# C64 register map
Vendor: Commodore Business Machines; Series: Commodore 64; File version: 0.1.0
CPU: other r0p0, little endian, no MPU, no FPU, 2 interrupt priority bits
Registers are 8-bit, read-write, no defined reset value unless marked. A register's access mark holds for its fields unless they carry their own. Offsets are from the block's base; [hi:lo] are bit positions; {n}, {i} and the like mark numbered series; 'fields as' and 'values as' point back to an identical list.

## CIA1 — MOS 6526 CIA 1 at 0xDC00 (image repeats every 0x10 bytes through 0xDCFF): keyboard matrix, joysticks, paddle select, Datassette read (FLAG1), timers. IRQ output drives the 6510 IRQ line. TOD pin receives mains-derived 50/60 Hz. SP1/CNT1 are available on the user port.
Base 0x0000DC00
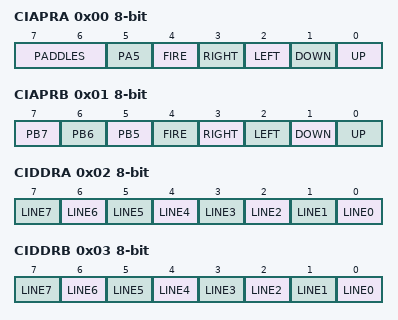
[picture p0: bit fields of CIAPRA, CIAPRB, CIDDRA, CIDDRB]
0x00 CIAPRA — Port A. Doubles as keyboard-matrix column drive (outputs, active low) and joystick port 2 (bits 0-4, active low). Bits 6-7 select which control port's paddles reach SID POTX/POTY.
  [7:6] PADDLES — Selects which control port's paddles are digitized by SID POTX/POTY: 1 = port 1, 2 = port 2
    1=Port1; 2=Port2
  [5] PA5 — Keyboard column 5
  [4] FIRE — Joystick 2 fire (also keyboard column 4). Active low.
    0=Pressed; 1=Released
  [3] RIGHT — Joystick 2 right (also keyboard column 3). Active low.
    0=Pushed; 1=Released
  [2] LEFT — Joystick 2 left (also keyboard column 2). Active low.
    0=Pushed; 1=Released
  [1] DOWN — Joystick 2 down (also keyboard column 1). Active low.
    0=Pushed; 1=Released
  [0] UP — Joystick 2 up (also keyboard column 0). Active low.
    0=Pushed; 1=Released
0x01 CIAPRB — Port B. Doubles as keyboard-matrix row sense (inputs, active low) and joystick port 1 (bits 0-4, active low; the fire line also triggers the light pen). PB6/PB7 can output timer A/B underflow.
  [7] PB7 — Timer B underflow output when CIACRB.SELECT_TIMER_OUTPUT is set; otherwise general I/O
  [6] PB6 — Timer A underflow output when CIACRA.SELECT_TIMER_OUTPUT is set; otherwise general I/O
  [5] PB5 — Keyboard row 5
  [4] FIRE — Joystick 1 fire, also the light pen trigger (also keyboard row 4). Active low.
    0=Pressed; 1=Released
  [3] RIGHT — Joystick 1 right (also keyboard row 3). Active low.
    0=Pushed; 1=Released
  [2] LEFT — Joystick 1 left (also keyboard row 2). Active low.
    0=Pushed; 1=Released
  [1] DOWN — Joystick 1 down (also keyboard row 1). Active low.
    0=Pushed; 1=Released
  [0] UP — Joystick 1 up (also keyboard row 0). Active low.
    0=Pushed; 1=Released
0x02 CIDDRA — Port A data direction (1 = output)
  [all] fields
    0=Input; 1=Output
  [n] LINE{n} (n=0..7) — Direction of Data Port A bit {n}
0x03 CIDDRB — Port B data direction (1 = output)
  [all] fields
    0=Input; 1=Output
  [n] LINE{n} (n=0..7) — Direction of Data Port B bit {n}
0x04 TIMALO — Timer A bits 7:0. Read: current count. Write: latch (reload value). HI/LO reads are not latched together, so a 16-bit read can tear across a decrement: read HI, LO, re-read HI and retry on change, or stop the timer.
  [7:0] TIMER — Timer A, low 8 bits (read: counter; write: latch)
0x05 TIMAHI — Timer A bits 15:8. Read: current count. Write: latch; if the timer is stopped, writing also loads the counter.
  [7:0] TIMER — Timer A, high 8 bits (read: counter; write: latch)
0x06 TIMBLO — Timer B bits 7:0 (as TALO)
  [7:0] TIMER — Timer B, low 8 bits (read: counter; write: latch)
0x07 TIMBHI — Timer B bits 15:8 (as TAHI)
  [7:0] TIMER — Timer B, high 8 bits (read: counter; write: latch)
0x08 TODTEN — TOD tenths of seconds, BCD. SIDE-EFFECT: reading releases the latch set by reading TODHRS; writing (in clock mode) restarts the clock; CIACRB.TOD_WRITE_MODE selects whether writes set the clock or the alarm.
  [3:0] TENTHS — Tenths, BCD
0x09 TODSEC — TOD seconds, BCD. SIDE-EFFECT: writes set the clock or the alarm per CIACRB.TOD_WRITE_MODE; the read value is frozen while the TODHRS/TODTEN latch is held.
  [6:0] SECONDS — Seconds 00-59, BCD
0x0A TODMIN — TOD minutes, BCD. SIDE-EFFECT: writes set the clock or the alarm per CIACRB.TOD_WRITE_MODE; the read value is frozen while the TODHRS/TODTEN latch is held.
  [6:0] MINUTES — Minutes 00-59, BCD
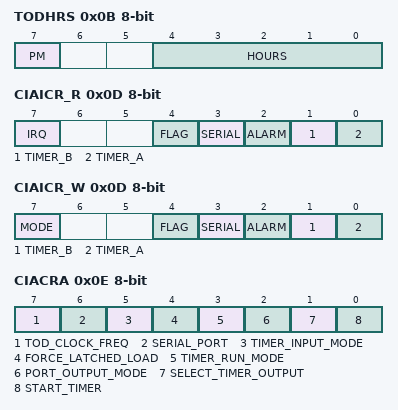
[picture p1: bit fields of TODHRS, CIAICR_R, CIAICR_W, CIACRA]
0x0B TODHRS — TOD hours, BCD, 12-hour with PM flag. SIDE-EFFECT: reading latches all four TOD registers until TODTEN is read; writing (in clock mode) stops the clock until TODTEN is written; CIACRB.TOD_WRITE_MODE selects whether writes set the clock or the alarm.
  [7] PM — 1 = PM
    0=Am; 1=Pm
  [4:0] HOURS — Hours 01-12, BCD
0x0C CIASDR — Serial shift register on SP pin, clocked by CNT; direction set by CRA.SPMODE. Output rate is timer A underflow / 2.
  [7:0] DATA — Serial shift-register byte
0x0D CIAICR_R ro read-clears — Interrupt data (read-only view of 0xDC0D, asserts IRQ): which sources have fired. Bit 7 (IR) reads Latched if any enabled source is pending. SIDE-EFFECT: reading clears all flags and releases the line, so capture everything from one read. Set the mask via CIAICR_W.
  [all] fields
    0=Inactive; 1=Latched
  [7] IRQ — Any enabled source latched (this read also clears all flags)
  [4] FLAG — FLAG pin negative edge (CIA1: Datassette read)
  [3] SERIAL — Serial register full/empty
  [2] ALARM — TOD alarm match
  [1] TIMER_B — Timer B underflow
  [0] TIMER_A — Timer A underflow
0x0D CIAICR_W wo (alternate view of CIAICR_R) — Interrupt mask (write-only alternate view of 0xDC0D). Enable or disable individual interrupt sources without disturbing the others: `set()` the sources you want to change, then let `mode()` pick the direction — `mode().enabled()` enables every source you `set()`, `mode().disabled()` disables them. Sources left `clear()` (the default) are untouched either way. Read status via CIAICR_R. SIDE-EFFECT: this write changes which interrupts are enabled.
  [7] MODE — Direction for this write: `enabled()` enables every source bit you `set()`; `disabled()` disables them. Sources left `clear()` are untouched either way. SIDE-EFFECT: the (un)mask takes effect immediately.
    0=Disabled; 1=Enabled
  [4] FLAG — FLAG interrupt mask select. `set()` marks the FLAG source for change; the direction (enable vs disable) comes from `mode()`. `clear()` (default) leaves it untouched. Setting this alone does nothing without `mode()`.
    0=Clear (Leave this source's mask unchanged); 1=Set (Select this source for the update chosen by MODE)
  [3] SERIAL — Serial interrupt mask select. `set()` marks the serial source for change; the direction (enable vs disable) comes from `mode()`. `clear()` (default) leaves it untouched. Setting this alone does nothing without `mode()`.
    values as FLAG
  [2] ALARM — TOD alarm interrupt mask select. `set()` marks the alarm for change; the direction (enable vs disable) comes from `mode()`. `clear()` (default) leaves it untouched. Setting this alone does nothing without `mode()`.
    values as FLAG
  [1] TIMER_B — Timer B interrupt mask select. `set()` marks Timer B for change; the direction (enable vs disable) comes from `mode()`. `clear()` (default) leaves Timer B untouched. Setting this alone does nothing without `mode()`.
    values as FLAG
  [0] TIMER_A — Timer A interrupt mask select. `set()` marks Timer A for change; the direction (enable vs disable) comes from `mode()`. `clear()` (default) leaves Timer A untouched. Setting this alone does nothing without `mode()`.
    values as FLAG
0x0E CIACRA — Control register A. Bit 4 (FORCE_LATCHED_LOAD) is a write-only strobe that always reads back 0, so it appears on the writer only
  [7] TOD_CLOCK_FREQ — TOD clock input frequency
    0=Hz60; 1=Hz50
  [6] SERIAL_PORT — Serial-port shift-register direction
    0=Input; 1=Output
  [5] TIMER_INPUT_MODE — What timer A counts
    0=CpuCycles; 1=UserPortCnt
  [4] FORCE_LATCHED_LOAD wo — Force-load timer A from its latch. A strobe: writing Execute performs the load, writing Idle does nothing. Write-only, hence no reader: the bit always reads back Idle no matter what was last written, so a read carries no information about the hardware. SIDE-EFFECT: writing Execute copies the latch into the counter immediately.
    0=Idle; 1=Execute
  [3] TIMER_RUN_MODE — Timer A reload behavior after underflow
    0=Continuous; 1=OneShot
  [2] PORT_OUTPUT_MODE — PB6 output waveform on timer A underflow
    0=PulseBit6; 1=ToggleBit6
  [1] SELECT_TIMER_OUTPUT — Route timer A underflow onto PB6 (Enabled) instead of using it as general I/O (Disabled)
    0=Disabled; 1=Enabled
  [0] START_TIMER — Start/stop timer A. SIDE-EFFECT: writing Enabled begins the count immediately.
    0=Disabled; 1=Enabled
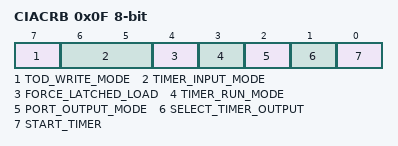
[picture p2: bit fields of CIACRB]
0x0F CIACRB — Control register B. Bit 4 (FORCE_LATCHED_LOAD) is a write-only strobe that always reads back 0, so it appears on the writer only
  [7] TOD_WRITE_MODE — Selects what TOD register writes set: clock or alarm
    0=Clock; 1=Alarm
  [6:5] TIMER_INPUT_MODE — What timer B counts
    0=CpuCycles; 1=UserPortCnt; 2=TaUnderflow; 3=TaUnderflowWhileCntHigh
  [4] FORCE_LATCHED_LOAD wo — Force-load timer B from its latch. A strobe: writing Execute performs the load, writing Idle does nothing. Write-only, hence no reader: the bit always reads back Idle no matter what was last written, so a read carries no information about the hardware. SIDE-EFFECT: writing Execute copies the latch into the counter immediately.
    0=Idle; 1=Execute
  [3] TIMER_RUN_MODE — Timer B reload behavior after underflow
    0=Continuous; 1=OneShot
  [2] PORT_OUTPUT_MODE — PB7 output waveform on timer B underflow
    0=PulseBit7; 1=ToggleBit7
  [1] SELECT_TIMER_OUTPUT — Route timer B underflow onto PB7 (Enabled) instead of using it as general I/O (Disabled)
    0=Disabled; 1=Enabled
  [0] START_TIMER — Start/stop timer B. SIDE-EFFECT: writing Enabled begins the count immediately.
    0=Disabled; 1=Enabled
